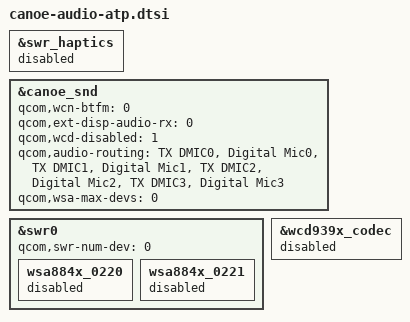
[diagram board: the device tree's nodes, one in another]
// SPDX-License-Identifier: BSD-3-Clause
/*
 * Copyright (c) 2023-2024 Qualcomm Innovation Center, Inc. All rights reserved.
 */

#include "canoe-audio-cdp.dtsi"

&swr_haptics {
	status = "disabled";
};

&canoe_snd {
	qcom,wcn-btfm = <0>;
	qcom,ext-disp-audio-rx = <0>;
	qcom,wcd-disabled =<1>;
	qcom,audio-routing =
		"TX DMIC0", "Digital Mic0",
		"TX DMIC1", "Digital Mic1",
		"TX DMIC2", "Digital Mic2",
		"TX DMIC3", "Digital Mic3";
	qcom,wsa-max-devs = <0>;
};

&swr0 {
	qcom,swr-num-dev = <0>;
	wsa884x_0220 {
		status = "disabled";
	};

	wsa884x_0221 {
		status = "disabled";
	};
};

&wcd939x_codec {
	status = "disabled";
};
